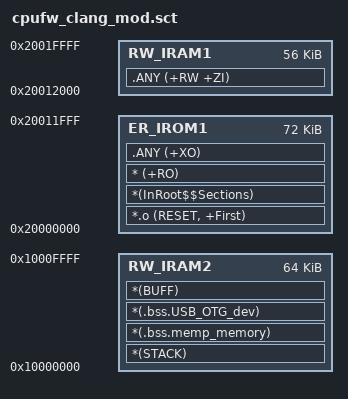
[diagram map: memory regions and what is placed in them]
; *************************************************************
; *** Scatter-Loading Description File generated by uVision ***
; *************************************************************

LR_IROM1 0x20000000 0x00012000  {    ; load region size_region
  ER_IROM1 0x20000000 0x00012000  {  ; load address = execution address
   *.o (RESET, +First)
   *(InRoot$$Sections)
   * (+RO)
   .ANY (+XO)
  }
  RW_IRAM1 0x20012000 0x0000E000  {  ; RW data
   .ANY (+RW +ZI)
   
  }
  RW_IRAM2 0x10000000 0x00010000  {
   ;*(HEAP)   
   *(STACK)   
   ;memp.o(.bss)
   ;mem.o(.bss)
   *(.bss.memp_memory)
   *(.bss.USB_OTG_dev)
   *(BUFF)
   ;usbd_rndis_core.o(.bss)
  }
}

